# STM32WB1Mxx register map
File version: 1.0
Registers are 32-bit, read-write, reset 0x0 unless marked. A register's access mark holds for its fields unless they carry their own. Offsets are from the block's base; [hi:lo] are bit positions; {n}, {i} and the like mark numbered series.

## EXTI — Async Interrupts and Events Controller
Base 0x58000800
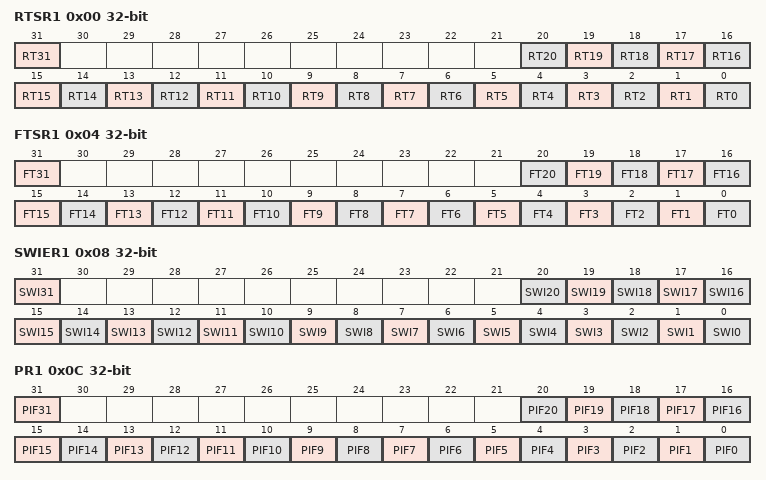
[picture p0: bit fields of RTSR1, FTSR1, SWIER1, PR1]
0x00 RTSR1 — EXTI rising trigger selection register [31:0]
  [31] RT31 — Rising trigger event configuration bit of line 31
  [n] RT{n} (n=0..20) — Rising trigger event configuration bit of line {n}
0x04 FTSR1 — EXTI falling trigger selection register [31:0]
  [31] FT31 — Falling trigger event configuration bit of line 31
  [n] FT{n} (n=0..20) — Falling trigger event configuration bit of line {n}
0x08 SWIER1 — EXTI software interrupt event register [31:0]
  [31] SWI31 — Software Interrupt on line 31
  [n] SWI{n} (n=0..20) — Software Interrupt on line {n}
0x0C PR1 — EXTI pending register [31:0]
  [31] PIF31 — Pending bit for line 31
  [n] PIF{n} (n=0..20) — Pending bit for line {n}
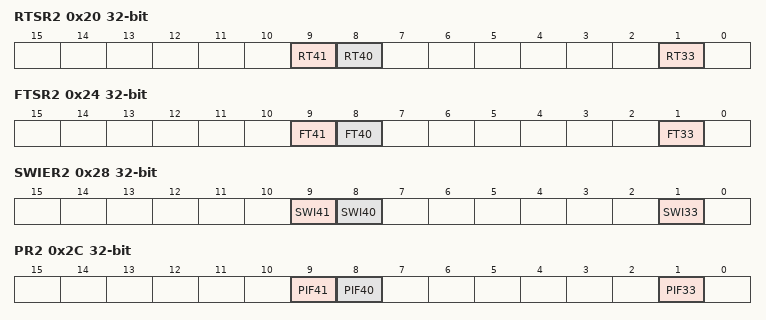
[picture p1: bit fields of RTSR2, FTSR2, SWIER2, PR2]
0x20 RTSR2 — EXTI rising trigger selection register [31:0]
  [9] RT41 — Rising trigger event configuration bit of line 41
  [8] RT40 — Rising trigger event configuration bit of line 40
  [1] RT33 — Rising trigger event configuration bit of line 33
0x24 FTSR2 — EXTI falling trigger selection register [31:0]
  [9] FT41 — Falling trigger event configuration bit of line 41
  [8] FT40 — Falling trigger event configuration bit of line 40
  [1] FT33 — Falling trigger event configuration bit of line 33
0x28 SWIER2 — EXTI software interrupt event register [31:0]
  [9] SWI41 — Software Interrupt on line 41
  [8] SWI40 — Software Interrupt on line 40
  [1] SWI33 — Software Interrupt on line 33
0x2C PR2 — EXTI pending register [31:0]
  [9] PIF41 — Pending bit for line 41
  [8] PIF40 — Pending bit for line 40
  [1] PIF33 — Pending bit for line 33
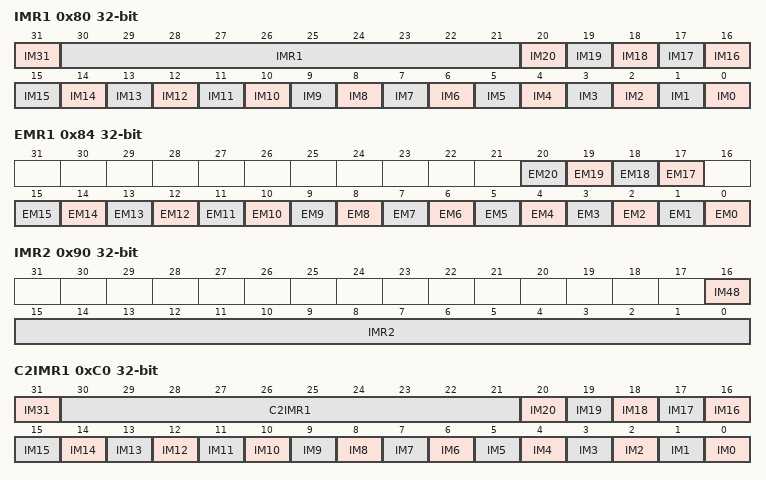
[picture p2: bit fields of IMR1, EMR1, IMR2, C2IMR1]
0x80 IMR1 — EXTI wakeup with interrupt mask register for cpu1 [31:0]
  [31] IM31 — CPU1 Interrupt Mask on line 31
  [30:21] IMR1
  [n] IM{n} (n=0..20) — CPU1 Interrupt Mask on line {n}
0x84 EMR1 — EXTI wakeup with event mask register for cpu1 [31:0]
  [n] EM{n} (n=17..20) — CPU1 Event Mask on line {n}
  [n] EM{n} (n=0..15) — CPU1 Event Mask on line {n}
0x90 IMR2 — EXTI wakeup with interrupt mask register for cpu1 [31:0]
  [16] IM48 — CPU1 Interrupt Mask on line 48
  [15:0] IMR2
0x94 EMR2 — EXTI wakeup with event mask register for cpu1 [31:0]
  [9:8] EMR2
0xC0 C2IMR1 — EXTI wakeup with interrupt mask register for cpu2 [31:0]
  [31] IM31 — CPU2 Interrupt Mask on line 31
  [30:21] C2IMR1
  [n] IM{n} (n=0..20) — CPU2 Interrupt Mask on line {n}
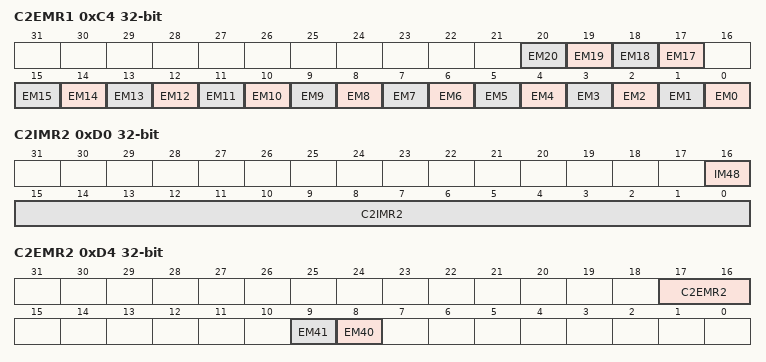
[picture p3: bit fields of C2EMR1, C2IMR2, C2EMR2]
0xC4 C2EMR1 — EXTI wakeup with event mask register for cpu2 [31:0]
  [n] EM{n} (n=17..20) — CPU2 Event Mask on line {n}
  [n] EM{n} (n=0..15) — CPU2 Event Mask on line {n}
0xD0 C2IMR2 — EXTI wakeup with interrupt mask register for cpu2 [31:0]
  [16] IM48 — CPU2 Interrupt Mask on line 48
  [15:0] C2IMR2
0xD4 C2EMR2 — EXTI wakeup with event mask register for cpu2 [31:0]
  [17:16] C2EMR2
  [9] EM41 — CPU2 Event Mask on line 41
  [8] EM40 — CPU2 Event Mask on line 40

## IPCC — Inter-Processor Communication
Base 0x58000C00
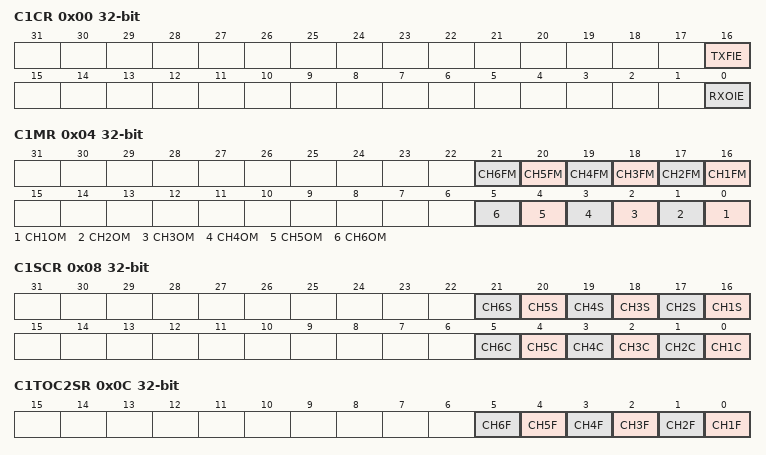
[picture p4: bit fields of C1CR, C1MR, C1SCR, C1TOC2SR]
0x00 C1CR — Inter-Processor Communication: C1 control register
  [16] TXFIE — Processor M4 Transmit channel free interrupt enable
  [0] RXOIE — Processor M4 Receive channel occupied interrupt enable
0x04 C1MR — Inter-Processor Communication: C1 mask register
  [n+15] CH{n}FM (n=1..6) — M4 Transmit Channel{n} free interrupt mask
  [n-1] CH{n}OM (n=1..6) — M4 Channel{n} occupied interrupt mask
0x08 C1SCR — Inter-Processor Communication: C1 status set clear register
  [n+15] CH{n}S (n=1..6) — M4 transmit Channel{n} status set
  [n-1] CH{n}C (n=1..6) — M4 receive Channel{n} status clear
0x0C C1TOC2SR — Inter-Processor Communication: C1 to processor M4 status register
  [n-1] CH{n}F (n=1..6) — M4 transmit to M4 receive Channel{n} status flag before masking
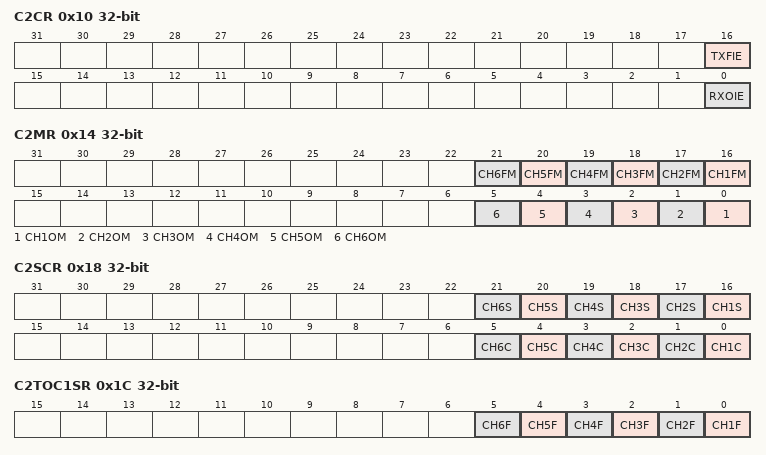
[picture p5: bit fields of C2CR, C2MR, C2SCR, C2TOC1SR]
0x10 C2CR — Inter-Processor Communication: C2 control register
  [16] TXFIE — Processor M0+ Transmit channel free interrupt enable
  [0] RXOIE — Processor M0+ Receive channel occupied interrupt enable
0x14 C2MR — Inter-Processor Communication: C2 mask register
  [n+15] CH{n}FM (n=1..6) — M0+ Transmit Channel{n} free interrupt mask
  [n-1] CH{n}OM (n=1..6) — M0+ Channel{n} occupied interrupt mask
0x18 C2SCR — Inter-Processor Communication: C2 status set clear register
  [n+15] CH{n}S (n=1..6) — M0+ transmit Channel{n} status set
  [n-1] CH{n}C (n=1..6) — M0+ receive Channel{n} status clear
0x1C C2TOC1SR — Inter-Processor Communication: C2 to processor M4 status register
  [n-1] CH{n}F (n=1..6) — M0+ transmit to M0 receive Channel{n} status flag before masking
